/*---------GLOBAL DEFINITIONS-----------*/
LIN_description_file;
LIN_protocol_version = "2.1";
LIN_language_version = "2.1";
LIN_speed = 19.2 kbps;
/* ----------NODE DEFINITIONS---------- */
Nodes {
   Master:
      Gateway1, /* Master node name */
      5.0 ms, /* Time base */
      0.1 ms; /* Jitter */
   Slaves:
      Slave1,
      Slave2;
}
/* ----------SIGNAL DEFINITIONS---------- */
Signals {
   /* Signal_name : Size, Init, Publisher, Subscriber(s) */
   Cluster1Potentiometer1 : 8, 0x0, Slave1, Gateway1;
   Cluster1LightSensor1 : 8, 0x0, Slave1, Gateway1;
   Cluster1Slave1Error : 1, 0x0, Slave1, Gateway1;
   Cluster1Potentiometer2 : 8, 0x0, Slave2, Gateway1;
   Cluster1Slave2Error : 1, 0x0, Slave2, Gateway1;
   SlaveIdentifier : 2, 0x0, Gateway1, Slave1,Slave2;
   ResetSignal : 2, 0x0, Gateway1, Slave1,Slave2;
}
/* ----------DIAGNOSTIC SIGNAL DEFINITIONS---------- */
Diagnostic_signals {
   /* MasterReq Reserved Signals */
   MasterReqB0 : 8, 0;
   MasterReqB1 : 8, 0;
   MasterReqB2 : 8, 0;
   MasterReqB3 : 8, 0;
   MasterReqB4 : 8, 0;
   MasterReqB5 : 8, 0;
   MasterReqB6 : 8, 0;
   MasterReqB7 : 8, 0;
   /* SlaveResp Reserved Signals */
   SlaveRespB0 : 8, 0;
   SlaveRespB1 : 8, 0;
   SlaveRespB2 : 8, 0;
   SlaveRespB3 : 8, 0;
   SlaveRespB4 : 8, 0;
   SlaveRespB5 : 8, 0;
   SlaveRespB6 : 8, 0;
   SlaveRespB7 : 8, 0;
}
/* ----------UNCONDITIONAL FRAME DEFINITIONS---------- */
Frames {
   ResetFrame : 0x4, Gateway1 , 1 {
      ResetSignal , 0;
   }
   LedControl : 0x5, Gateway1 , 1 {
      SlaveIdentifier , 0;
   }
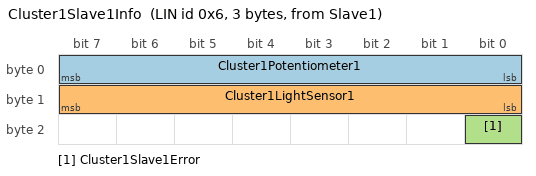
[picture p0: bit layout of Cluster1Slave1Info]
   Cluster1Slave1Info : 0x6, Slave1 , 3 {
      Cluster1Potentiometer1, 0;
      Cluster1LightSensor1, 8;
      Cluster1Slave1Error , 16;
   }
   Cluster1Slave2Info : 0x7, Slave2 , 2 {
      Cluster1Potentiometer2, 0;
      Cluster1Slave2Error , 8;
   }
}
/* ----------SPORADIC FRAME DEFINITIONS---------- */
Sporadic_frames {
   LedControlFrame : LedControl, ResetFrame;
   ResetControlFrame : ResetFrame, LedControl;
}
/* ----------DIAGNOSTIC FRAME DEFINITIONS---------- */
Diagnostic_frames {
   MasterReq : 0x3c {
      MasterReqB0 , 0;
      MasterReqB1 , 8;
      MasterReqB2 , 16;
      MasterReqB3 , 24;
      MasterReqB4 , 32;
      MasterReqB5 , 40;
      MasterReqB6 , 48;
      MasterReqB7 , 56;
   }
   SlaveResp : 0x3d {
      SlaveRespB0 , 0;
      SlaveRespB1 , 8;
      SlaveRespB2 , 16;
      SlaveRespB3 , 24;
      SlaveRespB4 , 32;
      SlaveRespB5 , 40;
      SlaveRespB6 , 48;
      SlaveRespB7 , 56;
   }
}
/* ----------NODE ATTRIBUTE DEFINITIONS---------- */
Node_attributes {
   Slave1 {
      LIN_protocol = "2.1"; /* Node protocol version */
      configured_NAD = 0x2; /* configured NAD of node (1-125) */
      initial_NAD = 0xb; /* initial NAD of node (1-125) */
      product_id = 0x1f, 0x2, 0x1; /* Product id */
      response_error = Cluster1Slave1Error; /* Response error signal */
      P2_min = 100 ms; /* P2_min */
      ST_min = 20 ms; /* ST_min */
      N_As_timeout = 1000 ms; /* N_As timeout value */
      N_Cr_timeout = 1000 ms; /* N_Cr timeout value */
      configurable_frames {
         LedControl;
         ResetFrame;
         Cluster1Slave1Info;
         LedControlFrame;
         ResetControlFrame;
      }
   }
   Slave2 {
      LIN_protocol = "2.1"; /* Node protocol version */
      configured_NAD = 0x3; /* configured NAD of node (1-125) */
      initial_NAD = 0xc; /* initial NAD of node (1-125) */
      product_id = 0x20, 0x3, 0x2; /* Product id */
      response_error = Cluster1Slave2Error; /* Response error signal */
      P2_min = 100 ms; /* P2_min */
      ST_min = 20 ms; /* ST_min */
      N_As_timeout = 1000 ms; /* N_As timeout value */
      N_Cr_timeout = 1000 ms; /* N_Cr timeout value */
      configurable_frames {
         LedControl;
         ResetFrame;
         Cluster1Slave2Info;
         LedControlFrame;
         ResetControlFrame;
      }
   }
}
/* ----------SCHEDULE TABLE DEFINITIONS---------- */
Schedule_tables {
   NormalTable {
      Cluster1Slave1Info delay 50.0 ms;
      Cluster1Slave2Info delay 50.0 ms;
      LedControlFrame delay 20.0 ms;
      ResetControlFrame delay 20.0 ms;
   }
   ResetTable {
      ResetControlFrame delay 50.0 ms;
   }
   PeriodicalWakeupTable {
      Cluster1Slave1Info delay 50.0 ms;
      Cluster1Slave2Info delay 50.0 ms;
      LedControlFrame delay 20.0 ms;
      ResetControlFrame delay 20.0 ms;
      FreeFormat {0, 255, 255, 255, 255, 255, 255, 255} delay 50.0 ms;
   }
}
